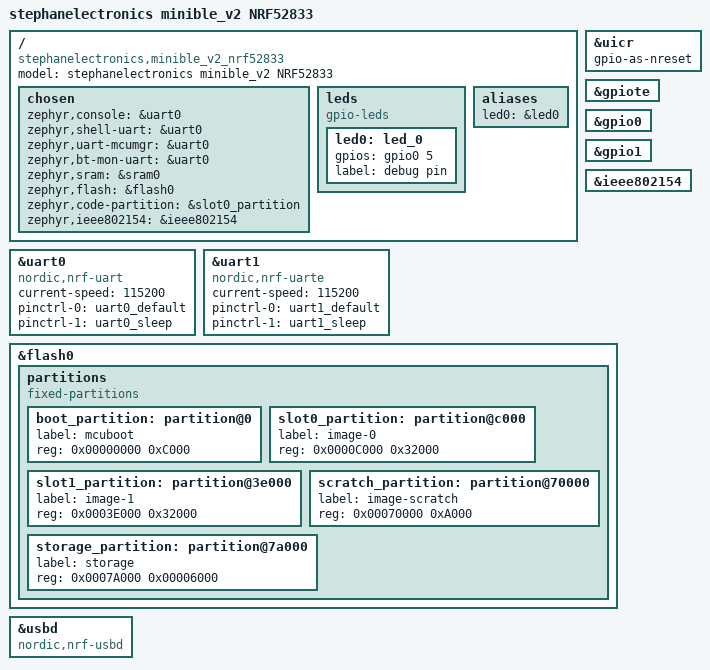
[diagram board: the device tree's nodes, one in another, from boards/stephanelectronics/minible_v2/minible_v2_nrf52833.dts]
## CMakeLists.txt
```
cmake_minimum_required(VERSION 3.20.0)
list(APPEND BOARD_ROOT ${CMAKE_CURRENT_SOURCE_DIR})
find_package(Zephyr REQUIRED HINTS $ENV{ZEPHYR_BASE})

project(aux_mcu_v2)

target_sources(app PRIVATE src/main.c)
```

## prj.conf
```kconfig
CONFIG_CLOCK_CONTROL_NRF_K32SRC_RC=y
CONFIG_NRFX_UARTE1=y
```

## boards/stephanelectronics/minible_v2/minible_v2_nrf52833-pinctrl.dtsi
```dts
/*
 * SPDX-License-Identifier: Apache-2.0
 */

&pinctrl {
	uart0_default: uart0_default {
		group1 {
			psels = <NRF_PSEL(UART_TX, 0, 2)>,
				<NRF_PSEL(UART_RX, 0, 3)>;
		};
	};

	uart0_sleep: uart0_sleep {
		group1 {
			psels = <NRF_PSEL(UART_TX, 0, 2)>,
				<NRF_PSEL(UART_RX, 0, 3)>;
			low-power-enable;
		};
	};
	
	uart1_default: uart1_default {
		group1 {
			psels = <NRF_PSEL(UART_TX, 0, 30)>,
				<NRF_PSEL(UART_RX, 0, 31)>,
				<NRF_PSEL(UART_RTS, 0, 28)>,
				<NRF_PSEL(UART_CTS, 0, 29)>;
		};
	};

	uart1_sleep: uart1_sleep {
		group1 {
			psels = <NRF_PSEL(UART_TX, 0, 30)>,
				<NRF_PSEL(UART_RX, 0, 31)>,
				<NRF_PSEL(UART_RTS, 0, 28)>,
				<NRF_PSEL(UART_CTS, 0, 29)>;
			low-power-enable;
		};
	};
};
```

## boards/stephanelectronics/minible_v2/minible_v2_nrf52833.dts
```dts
/dts-v1/;
#include <nordic/nrf52833_qiaa.dtsi>
#include "minible_v2_nrf52833-pinctrl.dtsi"

/ {
	model = "stephanelectronics minible_v2 NRF52833";
	compatible = "stephanelectronics,minible_v2_nrf52833";

	chosen {
		zephyr,console = &uart0;
		zephyr,shell-uart = &uart0;
		zephyr,uart-mcumgr = &uart0;
		zephyr,bt-mon-uart = &uart0;
		zephyr,sram = &sram0;
		zephyr,flash = &flash0;
		zephyr,code-partition = &slot0_partition;
		zephyr,ieee802154 = &ieee802154;
	};

	leds {
		compatible = "gpio-leds";
		led0: led_0 {
			gpios = <&gpio0 5 GPIO_ACTIVE_HIGH>;
			label = "debug pin";
		};
	};

	aliases {
		led0 = &led0;
	};
};

&uicr {
	gpio-as-nreset;
};

&gpiote {
	status = "okay";
};

&gpio0 {
	status = "okay";
};

&gpio1 {
	status = "okay";
};

&uart0 {
	compatible = "nordic,nrf-uart";
	status = "okay";
	current-speed = <115200>;
	pinctrl-0 = <&uart0_default>;
	pinctrl-1 = <&uart0_sleep>;
	pinctrl-names = "default", "sleep";
};

&uart1 {
	compatible = "nordic,nrf-uarte";
	status = "okay";
	current-speed = <115200>;
	pinctrl-0 = <&uart1_default>;
	pinctrl-1 = <&uart1_sleep>;
	pinctrl-names = "default", "sleep";
};

&ieee802154 {
	status = "okay";
};

&flash0 {
	partitions {
		compatible = "fixed-partitions";
		#address-cells = <1>;
		#size-cells = <1>;

		boot_partition: partition@0 {
			label = "mcuboot";
			reg = <0x00000000 0xC000>;
		};
		slot0_partition: partition@c000 {
			label = "image-0";
			reg = <0x0000C000 0x32000>;
		};
		slot1_partition: partition@3e000 {
			label = "image-1";
			reg = <0x0003E000 0x32000>;
		};
		scratch_partition: partition@70000 {
			label = "image-scratch";
			reg = <0x00070000 0xA000>;
		};
		storage_partition: partition@7a000 {
			label = "storage";
			reg = <0x0007A000 0x00006000>;
		};
	};
};

zephyr_udc0: &usbd {
	compatible = "nordic,nrf-usbd";
	status = "okay";
};
```

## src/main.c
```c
/*
 * Copyright (c) 2016 Intel Corporation
 *
 * SPDX-License-Identifier: Apache-2.0
 */

#include <stdio.h>
#include <zephyr/kernel.h>
#include <zephyr/drivers/gpio.h>
#include <zephyr/drivers/uart.h>

/* 1000 msec = 1 sec */
#define SLEEP_TIME_MS   1000

/* The devicetree node identifier for the "led0" alias. */
#define LED0_NODE DT_ALIAS(led0)

// see https://github.com/Delsian/nrf_sdk/blob/master/examples/peripheral/experimental_libuarte/main.c

/*
 * A build error on this line means your board is unsupported.
 * See the sample documentation for information on how to fix this.
 */
static const struct gpio_dt_spec led = GPIO_DT_SPEC_GET(LED0_NODE, gpios);

int main(void)
{
	int ret;
	bool led_state = true;

	if (!gpio_is_ready_dt(&led)) {
		return 0;
	}

	ret = gpio_pin_configure_dt(&led, GPIO_OUTPUT_ACTIVE);
	if (ret < 0) {
		return 0;
	}

	while (1) {
		ret = gpio_pin_toggle_dt(&led);
		if (ret < 0) {
			return 0;
		}

		led_state = !led_state;
		printf("LED state: %s\n", led_state ? "ON" : "OFF");
		k_msleep(SLEEP_TIME_MS);
	}
	return 0;
}
```

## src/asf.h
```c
/**
 * \file
 *
 * \brief Autogenerated API include file for the Atmel Software Framework (ASF)
 *
 * Copyright (c) 2012 Atmel Corporation. All rights reserved.
 *
 * \asf_license_start
 *
 * \page License
 *
 * Redistribution and use in source and binary forms, with or without
 * modification, are permitted provided that the following conditions are met:
 *
 * 1. Redistributions of source code must retain the above copyright notice,
 *    this list of conditions and the following disclaimer.
 *
 * 2. Redistributions in binary form must reproduce the above copyright notice,
 *    this list of conditions and the following disclaimer in the documentation
 *    and/or other materials provided with the distribution.
 *
 * 3. The name of Atmel may not be used to endorse or promote products derived
 *    from this software without specific prior written permission.
 *
 * 4. This software may only be redistributed and used in connection with an
 *    Atmel microcontroller product.
 *
 * THIS SOFTWARE IS PROVIDED BY ATMEL "AS IS" AND ANY EXPRESS OR IMPLIED
 * WARRANTIES, INCLUDING, BUT NOT LIMITED TO, THE IMPLIED WARRANTIES OF
 * MERCHANTABILITY, FITNESS FOR A PARTICULAR PURPOSE AND NON-INFRINGEMENT ARE
 * EXPRESSLY AND SPECIFICALLY DISCLAIMED. IN NO EVENT SHALL ATMEL BE LIABLE FOR
 * ANY DIRECT, INDIRECT, INCIDENTAL, SPECIAL, EXEMPLARY, OR CONSEQUENTIAL
 * DAMAGES (INCLUDING, BUT NOT LIMITED TO, PROCUREMENT OF SUBSTITUTE GOODS
 * OR SERVICES; LOSS OF USE, DATA, OR PROFITS; OR BUSINESS INTERRUPTION)
 * HOWEVER CAUSED AND ON ANY THEORY OF LIABILITY, WHETHER IN CONTRACT,
 * STRICT LIABILITY, OR TORT (INCLUDING NEGLIGENCE OR OTHERWISE) ARISING IN
 * ANY WAY OUT OF THE USE OF THIS SOFTWARE, EVEN IF ADVISED OF THE
 * POSSIBILITY OF SUCH DAMAGE.
 *
 * \asf_license_stop
 *
 */

#ifndef ASF_H
#define ASF_H

/*
 * This file includes all API header files for the selected drivers from ASF.
 * Note: There might be duplicate includes required by more than one driver.
 *
 * The file is automatically generated and will be re-written when
 * running the ASF driver selector tool. Any changes will be discarded.
 */

// From module: Common SAM0 compiler driver
#include <compiler.h>
#include <status_codes.h>

// From module: Common build items for user board support templates
#include <user_board.h>

// From module: Delay routines
#include <delay.h>

// From module: EXTINT - External Interrupt (Callback APIs)
#include <extint.h>
#include <extint_callback.h>

// From module: Generic board support
#include <board.h>

// From module: Interrupt management - SAM implementation
#include <interrupt.h>

// From module: PORT - GPIO Pin Control
#include <port.h>

// From module: Part identification macros
#include <parts.h>

// From module: SERCOM Callback API
#include <sercom.h>
#include <sercom_interrupt.h>

// From module: SERCOM USART - Serial Communications (Callback APIs)
#include <usart.h>
#include <usart_interrupt.h>

// From module: SYSTEM - Clock Management for SAMD21/R21/DA/HA
#include <clock.h>
#include <gclk.h>

// From module: SYSTEM - Core System Driver
#include <system.h>

// From module: SYSTEM - I/O Pin Multiplexer
#include <pinmux.h>

// From module: SYSTEM - Interrupt Driver
#include <system_interrupt.h>

// From module: SYSTEM - Power Management for SAM D20/D21/R21/D09/D10/D11/DA/HA
#include <power.h>

// From module: SYSTEM - Reset Management for SAM D20/D21/R21/D09/D10/D11/DA/HA
#include <reset.h>

// From module: Standard serial I/O (stdio)
#include <stdio_serial.h>

// From module: TC - Timer Counter (Callback APIs)
#include <tc.h>
#include <tc_interrupt.h>

// From module: USART - Serial interface- SAM implementation for devices with only USART
#include <serial.h>

#endif // ASF_H
```

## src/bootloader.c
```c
/*
 * bootloader.c
 *
 * Created: 02/10/2018 22:12:51
 * Author : limpkin
 */ 
#include <string.h>
#include "platform_defines.h"
#include "driver_clocks.h"
#include "platform_io.h"
#include "dma.h"
#include "sam.h"
/* Bootloader flag at a given address */
volatile uint32_t bootloader_flag __attribute__((used,section (".bootloader_flag")));
/* Message about to be sent to main MCU */
aux_mcu_message_t main_mcu_send_message;

/**
 * \brief Function to start the application.
 */
static void start_application(void)
{
    /* Pointer to the Application Section */
    void (*application_code_entry)(void);

    /* Rebase the Stack Pointer */
    __set_MSP(*(uint32_t *)APP_START_ADDR);

    /* Rebase the vector table base address */
    SCB->VTOR = ((uint32_t)APP_START_ADDR & SCB_VTOR_TBLOFF_Msk);

    /* Load the Reset Handler address of the application */
    application_code_entry = (void (*)(void))(unsigned *)(*(unsigned *)(APP_START_ADDR + 4));

    /* Jump to user Reset Handler in the application */
    application_code_entry();
}

int main(void)
{
    /* Initialize the SAM system */
    SystemInit();
    
    /* Check for boot flag */
    if (bootloader_flag != BOOTLOADER_FLAG)
    {
        start_application();
    }
    
    /* Initialize system */
    clocks_start_48MDFLL();                                             // Switch to 48M main clock
    dma_init();                                                         // Initialize the DMA controller
    platform_io_init_aux_comms();                                       // Initialize aux comms   
    dma_main_mcu_init_rx_transfer();                                    // Initialize communication handling with main MCU
    
    /* Send message to main MCU to let it know we're ready to receive data */
    memset((void*)&main_mcu_send_message, 0x00, sizeof(aux_mcu_message_t));
    main_mcu_send_message.message_type = AUX_MCU_MSG_TYPE_BOOTLOADER;
    main_mcu_send_message.bootloader_message.command = BOOTLOADER_START_PROGRAMMING_COMMAND;
    main_mcu_send_message.payload_length1 = sizeof(main_mcu_send_message.bootloader_message.command);
    dma_main_mcu_init_tx_transfer((void*)&AUXMCU_SERCOM->USART.DATA.reg, (void*)&main_mcu_send_message, sizeof(aux_mcu_message_t)); 
    
    /* Automatic write, disable caching */
    NVMCTRL->CTRLB.bit.MANW = 0;
    NVMCTRL->CTRLB.bit.CACHEDIS = 1;
    
    /* Replace with your application code */
    while (1) 
    {
        /* Did we receive a message? */
        if (dma_main_mcu_other_msg_received != FALSE)
        {
            /* Check for write message and payload is a multiple of the nvm row size */
            if ((dma_main_mcu_temp_rcv_message.message_type == AUX_MCU_MSG_TYPE_BOOTLOADER) && (dma_main_mcu_temp_rcv_message.bootloader_message.command == BOOTLOADER_WRITE_COMMAND) && ((dma_main_mcu_temp_rcv_message.bootloader_message.write_command.size & (NVMCTRL_ROW_SIZE - 1)) == 0))
            {
                /* Program one or more rows */
                for (uint16_t offset = 0; offset < dma_main_mcu_temp_rcv_message.bootloader_message.write_command.size; offset+=NVMCTRL_ROW_SIZE)
                {
                    /* Compute write address */
                    uint32_t write_adddress = APP_START_ADDR + dma_main_mcu_temp_rcv_message.bootloader_message.write_command.address + offset;
                    
                    /* Erase complete row, composed of 4 pages */
                    while ((NVMCTRL->INTFLAG.reg & NVMCTRL_INTFLAG_READY) == 0);
                    NVMCTRL->ADDR.reg  = write_adddress / 2;
                    NVMCTRL->CTRLA.reg = NVMCTRL_CTRLA_CMD_ER | NVMCTRL_CTRLA_CMDEX_KEY;
                    
                    /* Flash bytes */
                    for (uint32_t j = 0; j < 4; j++)
                    {
                        /* Flash 4 consecutive pages */
                        while ((NVMCTRL->INTFLAG.reg & NVMCTRL_INTFLAG_READY) == 0);
                        for(uint32_t i = 0; i < NVMCTRL_ROW_SIZE/4; i+=2)
                        {                            
                            NVM_MEMORY[(write_adddress+j*(NVMCTRL_ROW_SIZE/4)+i)/2] = dma_main_mcu_temp_rcv_message.bootloader_message.write_command.payload_as_uint16_t[(offset+j*(NVMCTRL_ROW_SIZE/4)+i)/2];
                        }
                    }
                }
                
                /* Send message to main MCU to let it know we're ready to receive data */
                memset((void*)&main_mcu_send_message, 0x00, sizeof(aux_mcu_message_t));
                main_mcu_send_message.message_type = AUX_MCU_MSG_TYPE_BOOTLOADER;
                main_mcu_send_message.bootloader_message.command = BOOTLOADER_WRITE_COMMAND;
                main_mcu_send_message.payload_length1 = sizeof(main_mcu_send_message.bootloader_message.command);
                dma_main_mcu_init_tx_transfer((void*)&AUXMCU_SERCOM->USART.DATA.reg, (void*)&main_mcu_send_message, sizeof(aux_mcu_message_t)); 
            }
            
            /* Start app? */
            if ((dma_main_mcu_temp_rcv_message.message_type == AUX_MCU_MSG_TYPE_BOOTLOADER) && (dma_main_mcu_temp_rcv_message.bootloader_message.command == BOOTLOADER_START_APP_COMMAND))
            {
                bootloader_flag = 0;
                __disable_irq();
                __DMB();
                NVIC_SystemReset();
            }  
            
            /* Clear bool */
            dma_main_mcu_other_msg_received = FALSE; 
        }
    }
}
```

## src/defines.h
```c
/*!  \file     defines.h
*    \brief    Generic type defines
*    Created:  22/08/2018
*    Author:   Mathieu Stephan
*/
#ifndef DEFINES_H_
#define DEFINES_H_

#include <stdio.h>

/* Macros */
#define XSTR(x) STR(x)
#define STR(x) #x

/* Standard defines */
#define FALSE                   0
#define TRUE                    (!FALSE)
#define BOOTLOADER_FLAG         0xDEADBEEF

/* Enums */
typedef enum    {RETURN_NOK = -1, RETURN_OK = 0} ret_type_te;

/* Typedefs */
typedef void (*void_function_ptr_type_t)(void);
typedef uint16_t cust_char_t;
typedef ret_type_te RET_TYPE;
typedef uint32_t nat_type_t;
typedef int32_t BOOL;

#endif /* DEFINES_H_ */
```

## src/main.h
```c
/*
 * main.h
 *
 * Created: 22/08/2018 15:32:12
 *  Author: limpkin
 */ 


#ifndef MAIN_H_
#define MAIN_H_

#include "platform_defines.h"


/* Prototypes */
void main_standby_sleep(BOOL startup_run);
void main_set_bootloader_flag(void);
void main_platform_init(void);


#endif /* MAIN_H_ */
```

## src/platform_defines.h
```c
/*!  \file     platform_defines.h
*    \brief    Defines specific to our platform: SERCOMs, GPIOs...
*    Created:  22/08/2018
*    Author:   Mathieu Stephan
*/
#ifndef PLATFORM_DEFINES_H_
#define PLATFORM_DEFINES_H_

#ifndef BOOTLOADER
    #include <asf.h>
#endif  
#include "defines.h"

/**************** FIRMWARE DEFINES ****************/
#define FW_MAJOR    0
#define FW_MINOR    6

/* Changelog:
v0.2: added padding to USB comms 64B packet
v0.3: sleep problems solved
v0.4: discarding USB messages having the incorrect flip bit
v0.5: no comms signal handling
v0.6: dummy release

*/

/**************** SETUP DEFINES ****************/
/*  This project should be built differently
 *  depending on the Mooltipass version.
 *  Simply define one of these:
 *
 *  PLAT_V3_SETUP
 *  => MiniBLE v2 breakout, 13/06/2018
 * - MAIN_MCU_WAKE removed (AUX_Tx used for wakeup)
 * - FORCE_RESET_AUX removed (little added benefits)
 * - NO_COMMS added (see github pages)
 */
 #define PLAT_V3_SETUP
 
/* Features depending on the defined platform */
#if defined(PLAT_V3_SETUP)
     #define NO_SECURITY_BIT_CHECK
#endif

/* USB defines */
#define USB_VENDOR_ID               0x1209              // Vendor ID
#define USB_PRODUCT_ID              0x4321              // Product ID
#define USB_RAWHID_USAGE_PAGE       0xFF31              // HID usage page, after 0xFF00: vendor-defined
#define USB_RAWHID_USAGE            0x0074              // HID usage
#define USB_STR_MANUFACTURER_VAL    "SE"                // Manufacturer string
#define USB_STR_PRODUCT_VAL         "Mooltipass"        // Product string
#define USB_RAWHID_INTERFACE        0                   // Interface for the raw HID
#define USB_RAWHID_RX_ENDPOINT      1                   // Raw HID TX endpoint
#define USB_RAWHID_TX_ENDPOINT      2                   // Raw HID RX endpoint
#define USB_RAWHID_TX_SIZE          64                  // Raw HID transmit packet size
#define USB_RAWHID_RX_SIZE          64                  // Raw HID receive packet size
#define USB_KEYBOARD_INTERFACE      1                   // Interface for keyboard
#define USB_KEYBOARD_ENDPOINT       3                   // Endpoint number for keyboard
#define USB_KEYBOARD_SIZE           8                   // Endpoint size for keyboard
#define USB_WRITE_TIMEOUT   50                          // Timeout for writing in the pipe
#define USB_READ_TIMEOUT 4                              // Timeout for reading in the pipe

/* Bluetooth defies */
#define BLE_PLATFORM_NAME           "Mooltipass Mini"

/* Enums */
typedef enum {PIN_GROUP_0 = 0, PIN_GROUP_1 = 1} pin_group_te;
typedef uint32_t PIN_MASK_T;
typedef uint32_t PIN_ID_T;

/*********************************************/
/*  Bootloader and memory related defines    */
/*********************************************/
#ifdef FEATURE_NVM_RWWEE
    #define RWWEE_MEMORY ((volatile uint16_t *)NVMCTRL_RWW_EEPROM_ADDR)
#endif
/* Simply an array point to our internal memory */
#define NVM_MEMORY ((volatile uint16_t *)FLASH_ADDR)
/* Our firmware start address */
#define APP_START_ADDR (0x800)
/* Internal storage slot for settings storage */
#define SETTINGS_STORAGE_SLOT   0

/* GCLK ID defines */
#define GCLK_ID_48M             GCLK_CLKCTRL_GEN_GCLK0_Val
#define GCLK_ID_32K             GCLK_CLKCTRL_GEN_GCLK3_Val

/* ADC defines */
#if defined(PLAT_V3_SETUP)
    #define HCURSENSE_ADC_PIN_MUXPOS    ADC_INPUTCTRL_MUXPOS_PIN18_Val
    #define LCURSENSE_ADC_PIN_MUXPOS    ADC_INPUTCTRL_MUXPOS_PIN19_Val
#endif

/* SERCOM defines */
#if defined(PLAT_V3_SETUP)
    #define AUXMCU_GCLK_SERCOM_ID       GCLK_CLKCTRL_ID_SERCOM3_CORE_Val
    #define AUXMCU_APB_SERCOM_BIT       SERCOM3_
    #define AUXMCU_SERCOM               SERCOM3
    #define AUXMCU_RX_TXPO              1
    #define AUXMCU_TX_PAD               0
#endif

/* DMA channel descriptors */
#define DMA_DESCID_RX_COMMS         0
#define DMA_DESCID_TX_COMMS         1

/* External interrupts numbers */
#if defined(PLAT_V3_SETUP)
    #define NOCOMMS_EXTINT_NUM      2
    #define NOCOMMS_EIC_SENSE_REG   SENSE2
#endif

/* SERCOM trigger for flash data transfers */
#if defined(PLAT_V3_SETUP)
    #define AUX_MCU_SERCOM_RXTRIG           0x07
    #define AUX_MCU_SERCOM_TXTRIG           0x08
#endif

/* Speed defines */
#define CPU_SPEED_HF                48000000UL
#define CPU_SPEED_MF                8000000UL

/* PORT defines */
/* AUX MCU COMMS */
#if defined(PLAT_V3_SETUP)
    #define AUX_MCU_TX_GROUP        PIN_GROUP_0
    #define AUX_MCU_TX_PINID        16
#endif
#define AUX_MCU_TX_MASK             (1UL << AUX_MCU_TX_PINID)
#define AUX_MCU_TX_PMUX_ID          PORT_PMUX_PMUXO_D_Val
#if (AUX_MCU_TX_PINID % 2) == 1
    #define AUX_MCU_TX_PMUXREGID  PMUXO
#else
    #define AUX_MCU_TX_PMUXREGID  PMUXE
#endif

#if defined(PLAT_V3_SETUP)
    #define AUX_MCU_RX_GROUP        PIN_GROUP_0
    #define AUX_MCU_RX_PINID        17
#endif
#define AUX_MCU_RX_MASK             (1UL << AUX_MCU_RX_PINID)
#define AUX_MCU_RX_PMUX_ID          PORT_PMUX_PMUXO_D_Val
#if (AUX_MCU_RX_PINID % 2) == 1
    #define AUX_MCU_RX_PMUXREGID  PMUXO
#else
    #define AUX_MCU_RX_PMUXREGID  PMUXE
#endif

#if defined(PLAT_V3_SETUP)
    #define AUX_MCU_NOCOMMS_GROUP   PIN_GROUP_0
    #define AUX_MCU_NOCOMMS_PINID   18
#endif
#define AUX_MCU_NOCOMMS_MASK        (1UL << AUX_MCU_NOCOMMS_PINID)
#if (AUX_MCU_NOCOMMS_PINID % 2) == 1
    #define AUX_MCU_NOCOMMS_PMUXREGID  PMUXO
#else
    #define AUX_MCU_NOCOMMS_PMUXREGID  PMUXE
#endif

/* BLE */
#if defined(PLAT_V3_SETUP)
    #define BLE_WAKE_OUT_GROUP   PIN_GROUP_0
    #define BLE_WAKE_OUT_PINID   15
#endif
#define BLE_WAKE_OUT_MASK        (1UL << BLE_WAKE_OUT_PINID)
#if (BLE_WAKE_OUT_PINID % 2) == 1
    #define BLE_WAKE_OUT_PMUXREGID  PMUXO
#else
    #define BLE_WAKE_OUT_PMUXREGID  PMUXE
#endif

#if defined(PLAT_V3_SETUP)
    #define BLE_EN_GROUP   PIN_GROUP_0
    #define BLE_EN_PINID   1
#endif
#define BLE_EN_MASK        (1UL << BLE_EN_PINID)
#if (BLE_EN_PINID % 2) == 1
    #define BLE_EN_PMUXREGID  PMUXO
#else
    #define BLE_EN_PMUXREGID  PMUXE
#endif

#if defined(PLAT_V3_SETUP)
    #define BLE_UART0_TX_GROUP   PIN_GROUP_0
    #define BLE_UART0_TX_PINID   8
#endif
#define BLE_UART0_TX_MASK        (1UL << BLE_UART0_TX_PINID)
#if (BLE_UART0_TX_PINID % 2) == 1
    #define BLE_UART0_TX_PMUXREGID  PMUXO
#else
    #define BLE_UART0_TX_PMUXREGID  PMUXE
#endif

#if defined(PLAT_V3_SETUP)
    #define BLE_UART1_TX_GROUP   PIN_GROUP_0
    #define BLE_UART1_TX_PINID   4
#endif
#define BLE_UART1_TX_MASK        (1UL << BLE_UART1_TX_PINID)
#if (BLE_UART1_TX_PINID % 2) == 1
    #define BLE_UART1_TX_PMUXREGID  PMUXO
#else
    #define BLE_UART1_TX_PMUXREGID  PMUXE
#endif

#if defined(PLAT_V3_SETUP)
    #define BLE_UART1_RTS_GROUP   PIN_GROUP_0
    #define BLE_UART1_RTS_PINID   6
#endif
#define BLE_UART1_RTS_MASK        (1UL << BLE_UART1_RTS_PINID)
#if (BLE_UART1_RTS_PINID % 2) == 1
    #define BLE_UART1_RTS_PMUXREGID  PMUXO
#else
    #define BLE_UART1_RTS_PMUXREGID  PMUXE
#endif

/* NiMH charging */
#if defined(PLAT_V3_SETUP)
    #define CHARGE_EN_GROUP   PIN_GROUP_0
    #define CHARGE_EN_PINID   22
#endif
#define CHARGE_EN_MASK        (1UL << CHARGE_EN_PINID)
#if (CHARGE_EN_PINID % 2) == 1
    #define CHARGE_EN_PMUXREGID  PMUXO
#else
    #define CHARGE_EN_PMUXREGID  PMUXE
#endif
#if defined(PLAT_V3_SETUP)
    #define MOS_CHARGE_GROUP   PIN_GROUP_0
    #define MOS_CHARGE_PINID   23
#endif
#define MOS_CHARGE_MASK        (1UL << MOS_CHARGE_PINID)
#if (MOS_CHARGE_PINID % 2) == 1
    #define MOS_CHARGE_PMUXREGID  PMUXO
#else
    #define MOS_CHARGE_PMUXREGID  PMUXE
#endif

#if defined(PLAT_V3_SETUP)
    #define HIGH_CUR_SENSE_GROUP     PIN_GROUP_0
    #define HIGH_CUR_SENSE_PINID     10
    #define HIGH_CUR_SENSE_MASK      (1UL << HIGH_CUR_SENSE_PINID)
    #define HIGH_CUR_SENSE_PMUX_ID   PORT_PMUX_PMUXE_B_Val
    #if (HIGH_CUR_SENSE_PINID % 2) == 1
        #define HIGH_CUR_SENSE_PMUXREGID PMUXO
    #else
        #define HIGH_CUR_SENSE_PMUXREGID PMUXE
    #endif
#endif

#if defined(PLAT_V3_SETUP)
    #define LOW_CUR_SENSE_GROUP     PIN_GROUP_0
    #define LOW_CUR_SENSE_PINID     11
    #define LOW_CUR_SENSE_MASK      (1UL << LOW_CUR_SENSE_PINID)
    #define LOW_CUR_SENSE_PMUX_ID   PORT_PMUX_PMUXE_B_Val
    #if (LOW_CUR_SENSE_PINID % 2) == 1
        #define LOW_CUR_SENSE_PMUXREGID PMUXO
    #else
        #define LOW_CUR_SENSE_PMUXREGID PMUXE
    #endif
#endif

#if defined(PLAT_V3_SETUP)
    #define DAC_GROUP     PIN_GROUP_0
    #define DAC_PINID     2
    #define DAC_MASK      (1UL << DAC_PINID)
    #define DAC_PMUX_ID   PORT_PMUX_PMUXE_B_Val
    #if (DAC_PINID % 2) == 1
        #define DAC_PMUXREGID PMUXO
    #else
        #define DAC_PMUXREGID PMUXE
    #endif
#endif

/* USB pads */
#if defined(PLAT_V3_SETUP)
    #define USB_DM_GROUP        PIN_GROUP_0
    #define USB_DM_PINID        24
#endif
#define USB_DM_MASK             (1UL << USB_DM_PINID)
#define USB_DM_PMUX_ID          PORT_PMUX_PMUXO_G_Val
#if (USB_DM_PINID % 2) == 1
    #define USB_DM_PMUXREGID    PMUXO
#else
    #define USB_DM_PMUXREGID    PMUXE
#endif

#if defined(PLAT_V3_SETUP)
    #define USB_DP_GROUP        PIN_GROUP_0
    #define USB_DP_PINID        25
#endif
#define USB_DP_MASK             (1UL << USB_DP_PINID)
#define USB_DP_PMUX_ID          PORT_PMUX_PMUXO_G_Val
#if (USB_DP_PINID % 2) == 1
    #define USB_DP_PMUXREGID    PMUXO
#else
    #define USB_DP_PMUXREGID    PMUXE
#endif

#endif /* PLATFORM_DEFINES_H_ */
```
